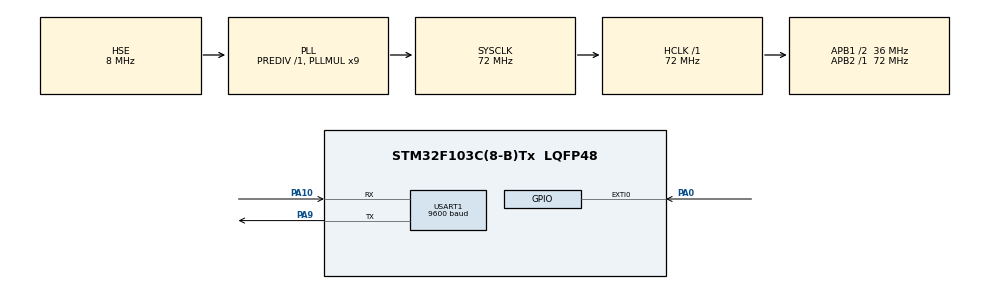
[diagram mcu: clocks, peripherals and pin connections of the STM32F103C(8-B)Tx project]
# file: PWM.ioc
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Mcu.Family=STM32F1
Mcu.Name=STM32F103C(8-B)Tx
Mcu.Package=LQFP48
NVIC.EXTI0_IRQn=true\:0\:0\:false\:false\:true\:true\:true\:true
NVIC.PriorityGroup=NVIC_PRIORITYGROUP_4
NVIC.TIM1_UP_IRQn=true\:0\:0\:false\:false\:true\:true\:true\:true
PA0-WKUP.GPIO_PuPd=GPIO_PULLDOWN
PA0-WKUP.Signal=GPXTI0
PA10.Mode=Asynchronous
PA10.Signal=USART1_RX
PA9.Mode=Asynchronous
PA9.Signal=USART1_TX
PD0-OSC_IN.Mode=HSE-External-Oscillator
PD0-OSC_IN.Signal=RCC_OSC_IN
PD1-OSC_OUT.Mode=HSE-External-Oscillator
PD1-OSC_OUT.Signal=RCC_OSC_OUT
ProjectManager.HeapSize=0x200
ProjectManager.StackSize=0x400
ProjectManager.TargetToolchain=MDK-ARM V5.32
RCC.AHBFreq_Value=72000000
RCC.APB1CLKDivider=RCC_HCLK_DIV2
RCC.APB1Freq_Value=36000000
RCC.APB1TimFreq_Value=72000000
RCC.APB2Freq_Value=72000000
RCC.APB2TimFreq_Value=72000000
RCC.HCLKFreq_Value=72000000
RCC.PLLMUL=RCC_PLL_MUL9
RCC.PLLSourceVirtual=RCC_PLLSOURCE_HSE
RCC.SYSCLKFreq_VALUE=72000000
RCC.SYSCLKSource=RCC_SYSCLKSOURCE_PLLCLK
RCC.USBFreq_Value=72000000
TIM1.Period=10000-1
TIM1.Prescaler=720-1
USART1.BaudRate=9600
USART1.VirtualMode=VM_ASYNC
VP_SYS_VS_ND.Mode=No_Debug
VP_TIM1_VS_ClockSourceINT.Mode=Internal
board=custom

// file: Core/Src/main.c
/* USER CODE BEGIN Header */
/**
  ******************************************************************************
  * @file           : main.c
  * @brief          : Main program body
  ******************************************************************************
  * @attention
  *
  * Copyright (c) 2024 STMicroelectronics.
  * All rights reserved.
  *
  * This software is licensed under terms that can be found in the LICENSE file
  * in the root directory of this software component.
  * If no LICENSE file comes with this software, it is provided AS-IS.
  *
  ******************************************************************************
  */
/* USER CODE END Header */
#include "main.h"
#include "tim.h"
#include "usart.h"
#include "gpio.h"

/* USER CODE BEGIN Includes */
#include "stdio.h"
/* USER CODE END Includes */

/* USER CODE BEGIN PD */

#define USER_MAIN_DEBUG
#ifdef USER_MAIN_DEBUG
  #define user_main_printf(format, ...) printf( format "\r\n", ##__VA_ARGS__)
  #define user_main_info(format, ...) printf("[\tmain]info:" format "\r\n", ##__VA_ARGS__)
  #define user_main_debug(format, ...) printf("[\tmain]debug:" format "\r\n", ##__VA_ARGS__)
  #define user_main_error(format, ...) printf("[\tmain]error:" format "\r\n",##__VA_ARGS__)
#else
  #define user_main_printf(format, ...)
  #define user_main_info(format, ...)
  #define user_main_debug(format, ...)
  #define user_main_error(format, ...)
#endif

/* USER CODE END PD */

/* USER CODE BEGIN PV */
int pwm_value_final = 0;
/* USER CODE END PV */

void SystemClock_Config(void);

/* USER CODE BEGIN 0 */
int fputc(int ch, FILE *f) {
  uint8_t temp[1] = {ch};
  HAL_UART_Transmit(&huart1, temp, 1, 2);
  return ch;
}
/* USER CODE END 0 */

int main(void)
{

  /* MCU Configuration--------------------------------------------------------*/

  /* Reset of all peripherals, Initializes the Flash interface and the Systick. */
  HAL_Init();

  /* Configure the system clock */
  SystemClock_Config();

  /* Initialize all configured peripherals */
  MX_GPIO_Init();
  MX_USART1_UART_Init();
  MX_TIM1_Init();
  /* USER CODE BEGIN 2 */

  // 定时器1使能
  HAL_TIM_Base_Start_IT(&htim1);

  /* USER CODE END 2 */

  /* Infinite loop */
  /* USER CODE BEGIN WHILE */
  while (1)
  {
    // 统计 1000ms 时间即为频率
//    pwm_value = 0;
//    HAL_Delay(1000);
//    user_main_debug("pwm_value -> %d Hz", pwm_value);
    user_main_debug("pwm_value -> %d Hz", pwm_value_final);

    /* USER CODE END WHILE */

  }
}

void SystemClock_Config(void)
{
  RCC_OscInitTypeDef RCC_OscInitStruct = {0};
  RCC_ClkInitTypeDef RCC_ClkInitStruct = {0};

  /** Initializes the RCC Oscillators according to the specified parameters
  * in the RCC_OscInitTypeDef structure.
  */
  RCC_OscInitStruct.OscillatorType = RCC_OSCILLATORTYPE_HSE;
  RCC_OscInitStruct.HSEState = RCC_HSE_ON;
  RCC_OscInitStruct.HSEPredivValue = RCC_HSE_PREDIV_DIV1;
  RCC_OscInitStruct.HSIState = RCC_HSI_ON;
  RCC_OscInitStruct.PLL.PLLState = RCC_PLL_ON;
  RCC_OscInitStruct.PLL.PLLSource = RCC_PLLSOURCE_HSE;
  RCC_OscInitStruct.PLL.PLLMUL = RCC_PLL_MUL9;
  if (HAL_RCC_OscConfig(&RCC_OscInitStruct) != HAL_OK)
  {
    Error_Handler();
  }

  /** Initializes the CPU, AHB and APB buses clocks
  */
  RCC_ClkInitStruct.ClockType = RCC_CLOCKTYPE_HCLK|RCC_CLOCKTYPE_SYSCLK
                              |RCC_CLOCKTYPE_PCLK1|RCC_CLOCKTYPE_PCLK2;
  RCC_ClkInitStruct.SYSCLKSource = RCC_SYSCLKSOURCE_PLLCLK;
  RCC_ClkInitStruct.AHBCLKDivider = RCC_SYSCLK_DIV1;
  RCC_ClkInitStruct.APB1CLKDivider = RCC_HCLK_DIV2;
  RCC_ClkInitStruct.APB2CLKDivider = RCC_HCLK_DIV1;

  if (HAL_RCC_ClockConfig(&RCC_ClkInitStruct, FLASH_LATENCY_2) != HAL_OK)
  {
    Error_Handler();
  }
}

/* USER CODE BEGIN 4 */
int pwm_sum, pwm_avg, pwm_value;

// 外部中断
void HAL_GPIO_EXTI_Callback(uint16_t GPIO_Pin)
{
  if (GPIO_Pin == GPIO_PIN_0)
  {
    pwm_value++;
  }
}

/* 定时器2配置为0.1s触发一次中断 */
/**
  * @brief 定时器中断的回调函数
  * @param htim 触发中断的定时器
  * @retval None
  */
void HAL_TIM_PeriodElapsedCallback(TIM_HandleTypeDef *htim) {
  if(htim-> Instance == htim1.Instance) {
    pwm_sum += pwm_value * 10; //pwm_sum累加
    pwm_sum -= pwm_avg; //pwm_sum减去上次的平均值
    pwm_avg = pwm_sum * 1.0 / 5; //更新pwm的平均值
    pwm_value_final = pwm_avg; //pwm_value_final的值即为当前pwm的频率
    pwm_value = 0; //将pwm_value清空， 重新计数
  }
}

/* USER CODE END 4 */

void Error_Handler(void)
{
  __disable_irq();
  while (1)
  {
  }
}
